# nrf7140_application register map
Vendor: Nordic Semiconductor; Series: nRF71; File version: 1
CPU: CM33 r0p4, little endian, MPU, FPU, 3 interrupt priority bits, 480 interrupts, 8 SAU regions
Registers are 32-bit, read-write, reset 0x0 unless marked. A register's access mark holds for its fields unless they carry their own. Offsets are from the block's base; [hi:lo] are bit positions; {n}, {i} and the like mark numbered series; 'fields as' and 'values as' point back to an identical list.

## GLOBAL_TBM_NS — Trace buffer monitor 0
Base 0xBF003000
Same registers: GLOBAL_TBM_S 0xBF003000 (alternate view of GLOBAL_TBM_NS)
0x00 TASKS_START wo — Start counter
  [0] TASKS_START
    1=Trigger task
0x04 TASKS_STOP wo — Stop counter, clear counter value
  [0] TASKS_STOP
    1=Trigger task
0x08 TASKS_FLUSH wo — Save current counter value to COUNTSNAPSHOT
  [0] TASKS_FLUSH
    1=Trigger task
0x100 EVENTS_HALFFULL — Counter value equals half-full
  [0] EVENTS_HALFFULL
    0=NotGenerated (Event not generated); 1=Generated (Event generated)
0x104 EVENTS_FULL — Counter value equals full
  [0] EVENTS_FULL
    values as EVENTS_HALFFULL.EVENTS_HALFFULL
0x108 EVENTS_FLUSH — Counter value saved to COUNTSNAPSHOT due to flush
  [0] EVENTS_FLUSH
    values as EVENTS_HALFFULL.EVENTS_HALFFULL
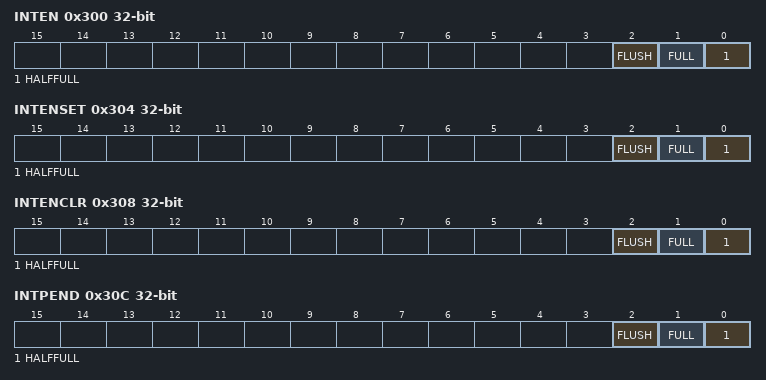
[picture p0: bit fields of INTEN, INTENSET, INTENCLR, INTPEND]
0x300 INTEN — Enable or disable interrupt
  [all] fields
    0=Disabled; 1=Enabled
  [2] FLUSH — Enable or disable interrupt for event FLUSH
  [1] FULL — Enable or disable interrupt for event FULL
  [0] HALFFULL — Enable or disable interrupt for event HALFFULL
0x304 INTENSET — Enable interrupt
  [all] fields
    on read: 0=Disabled (Read: Disabled); 1=Enabled (Read: Enabled) | on write: 1=Set (Enable)
  [2] FLUSH — Write '1' to enable interrupt for event FLUSH
  [1] FULL — Write '1' to enable interrupt for event FULL
  [0] HALFFULL — Write '1' to enable interrupt for event HALFFULL
0x308 INTENCLR — Disable interrupt
  [all] fields
    on read: 0=Disabled (Read: Disabled); 1=Enabled (Read: Enabled) | on write: 1=Clear (Disable)
  [2] FLUSH — Write '1' to disable interrupt for event FLUSH
  [1] FULL — Write '1' to disable interrupt for event FULL
  [0] HALFFULL — Write '1' to disable interrupt for event HALFFULL
0x30C INTPEND ro — Pending interrupts
  [all] fields
    on read: 0=NotPending (Read: Not pending); 1=Pending (Read: Pending)
  [2] FLUSH — Read pending status of interrupt for event FLUSH
  [1] FULL — Read pending status of interrupt for event FULL
  [0] HALFFULL — Read pending status of interrupt for event HALFFULL
0x400 BUFFERSIZE reset 0x400 — System RAM trace buffer total size in bytes
  [12:0] BUFFERSIZE — Must only be configured in STOP mode. Must be programmed to multiple of 16 bytes to make half-buffer size always 64 bit word aligned. Typical minimum BUFFERSIZE value 0x010 i.e. 16 bytes, typical maximum value 0x1000 i.e. 4096 bytes.
    0=Zero (0 bytes); 16=Min (16 bytes); 0x1000=Max (4096 bytes)
0x404 COUNT — Counter current value
  [12:0] COUNT — Counter current value. Only writable when counter is in stopped state. Writing when not in stopped state will generate a bus fault.
0x408 COUNTSNAPSHOT ro — Copy of the current COUNT value
  [12:0] COUNTSNAPSHOT — TASKS_FLUSH will copy the current COUNT value to this register.

## GLOBAL_MUTEX120_NS — MUTEX 0
Base 0x4F8D2000
Same registers: GLOBAL_MUTEX130_NS 0x4F927000
{0x400+4i} MUTEX[{i}] (i=0..31) — Description collection: Mutex register
  [0] MUTEX — Mutex register n
    0=Unlocked (Mutex n is in unlocked state); 1=Locked (Mutex n is in locked state)

## GLOBAL_PROTOTYPE_NS — Prototype HW information registers.
Base 0x4F8D2000; alternate view of GLOBAL_MUTEX120_NS
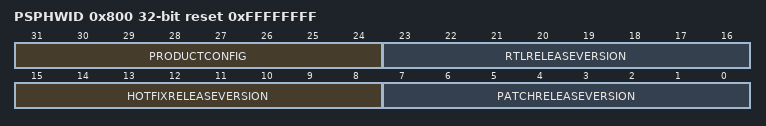
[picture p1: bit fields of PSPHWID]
0x800 PSPHWID ro reset 0xFFFFFFFF — PSP hardware ID register, unique ID for each prototype release. Used to identify RTL release that prototype is based on.
  [31:24] PRODUCTCONFIG
  [23:16] RTLRELEASEVERSION — First letter of RTL release version in ASCII corresponding to A-Z.
  [15:8] HOTFIXRELEASEVERSION
  [7:0] PATCHRELEASEVERSION — PSP patch/bugfix release version
0x804 FPGATIMESTAMP ro — 32-bit timestamp value stored by the FPGA bitstream in format ddddd_MMMM_yyyyyy_hhhhh_mmmmmm_ssssss. Unique for every FPGA netlist implementation, not dependent to RTL synthesis. 0x87654321 set in emulator database.
  [31:0] FPGATIMESTAMP — ddddd = 5 bits to represent 31 days in a month. MMMM = 4 bits to represent 12 months in a year. yyyyyy = 6 bits to represent 0 to 63 (to note year 2000 to 2063). hhhhh = 5 bits to represent 24 hours in a day. mmmmmm = 6 bits to represent 60 minutes in an hour. ssssss = 6 bits to represent 60 seconds in a minute.
0x808 EMULATORSPEEDVALUE ro — Used to store real speed of emulator is running. Used by SW to config UART speed etc, to ensure correct operation.
  [31:0] EMULATORSPEEDVALUE — Actual clock speed for FCLK 400M in emulator (Hz). In FPGA set to 0x0.
0x80C FPGACLOCKDIVIDERRATIO ro — Overall clock divider ratio for FPGA
  [31:0] FPGACLOCKDIVIDERRATIO — Overall clock divider ratio for FPGA. Set to 0 for emulator database.
